# AST1060 register map
File version: 1.0
CPU: CM4 r0p1, little endian, MPU, FPU, 4 interrupt priority bits, 256 interrupts
Registers are 32-bit, read-write, reset 0x0 unless marked. A register's access mark holds for its fields unless they carry their own. Offsets are from the block's base; [hi:lo] are bit positions; {n}, {i} and the like mark numbered series; 'fields as' and 'values as' point back to an identical list.

## secure
Base 0x7E6F2000
0x00 SECURE000 — Protection Key Register
  [31:0] ProtKey — Protection Key
0x04 SECURE004 — OTP Command Trigger Register
  [31:0] OTPCmdTriggerReg
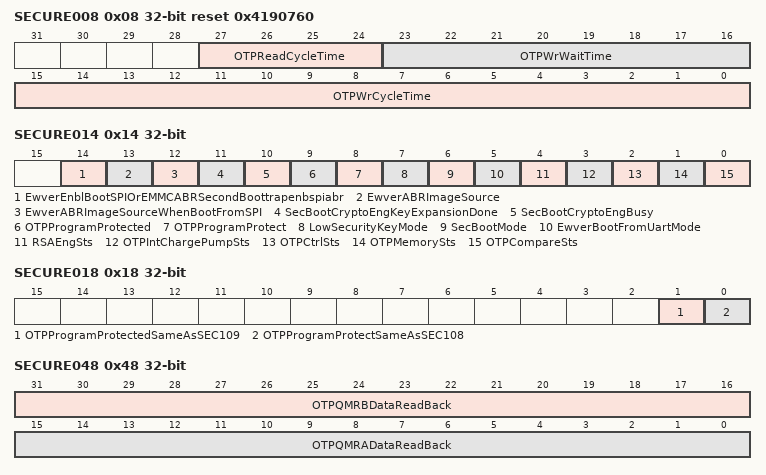
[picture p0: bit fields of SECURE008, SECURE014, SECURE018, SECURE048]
0x08 SECURE008 reset 0x4190760 — OTP Timing Register
  [27:24] OTPReadCycleTime
  [23:16] OTPWrWaitTime — OTP write wait time
  [15:0] OTPWrCycleTime — OTP write cycle time
0x10 SECURE010 — OTP Address Register
  [15:0] OTPAddrRegiste — OTP Address Registe
0x14 SECURE014 — Secure Engine Status Register
  [14] EwverEnblBootSPIOrEMMCABRSecondBoottrapenbspiabr ro — ewverEnable boot SPI or eMMC ABR (second boot)(trap_en_bspiabr
  [13] EwverABRImageSource ro
    0=First_ABR_Image; 1=Second_ABR_Image
  [12] EwverABRImageSourceWhenBootFromSPI ro
    0=First_ABR_Image_Source_When_Boot_From_SPI; 1=Second_ABR_Image_Source_When_Boot_From_SPI
  [11] SecBootCryptoEngKeyExpansionDone ro — Secure Boot Crypto Engine Key Expansion Done
    0=Crypto_Engine_Key_Expansion_Is_Busy; 1=Crypto_Engine_Key_Expansion_Is_Done
  [10] SecBootCryptoEngBusy ro — Secure Boot Crypto Engine Busy
    0=Crypto_Engine_Is_Idle; 1=Crypto_Engine_Is_Busy
  [9] OTPProgramProtected ro
    0=Last_OTP_Program_Command_Is_Completed; 1=Last_OTP_Program_Command_Is_Write_Protected
  [8] OTPProgramProtect ro
    0=SEC10_OTP_Address_Is_Not_Protected; 1=SEC10_OTP_Address_Is_Write_Protected
  [7] LowSecurityKeyMode ro
    0=Normal_Mode; 1=Low_Security_Mode_Is_Enabled
  [6] SecBootMode ro — Secure Boot Mode
    0=Normal_Mode; 1=Secure_Boot_Mode_Is_Enabled
  [5] EwverBootFromUartMode ro
    0=Boot_From_Uart_Mode; 1=Boot_From_SPI_Or_EMMC_Mode
  [4] RSAEngSts ro — RSA engine status
    0=RSA_Engine_Busy; 1=RSA_Engine_Ready
  [3] OTPIntChargePumpSts ro — OTP internal charge pump status
    0=OTP_Internal_Charge_Pump_Not_Ready; 1=OTP_Internal_Charge_Pump_Ready
  [2] OTPCtrlSts ro — OTP controller status
    0=OTP_Controller_Busy; 1=OTP_Controller_Idle
  [1] OTPMemorySts ro — OTP memory status
    0=OTP_Memory_Busy; 1=OTP_Memory_Idle
  [0] OTPCompareSts ro — OTP compare status
    0=Quad_DW_Read_Compare_Fail; 1=Quad_DW_Read_Compare_Pass
0x18 SECURE018 — OTP Programming Status Register
  [1] OTPProgramProtectedSameAsSEC109 ro
    values as SECURE014.OTPProgramProtected
  [0] OTPProgramProtectSameAsSEC108 ro
    values as SECURE014.OTPProgramProtect
0x20 SECURE020 — OTP Data Compare Register 1
  [31:0] OTPDataCompareReg1
0x24 SECURE024 — OTP Data Compare Register 2
  [31:0] OTPDataCompareReg2
0x28 SECURE028 — OTP Data Compare Register 3
  [31:0] OTPDataCompareReg3
0x2C SECURE02C — OTP Data Compare Register 4
  [31:0] OTPDataCompareReg4 ro
0x30 SECURE030 — OTPTRAP data read back 1
  [31:0] OTPTRAPDataReadBack1 ro
0x34 SECURE034 — OTPTRAP data read back 2
  [31:0] OTPTRAPDataReadBack2 ro
0x38 SECURE038 — OTP QRR data read back
  [31:0] OTPQRRDataReadBack ro
0x40 SECURE040 — OTP QSR data read back
  [31:0] OTPQSRDataReadBack ro
0x44 SECURE044 — OTP QMR data read back
  [31:0] OTPQMRDataReadBack ro
0x48 SECURE048 — OTP QMRA and QMRB data read back
  [31:16] OTPQMRBDataReadBack ro, [15:0] OTPQMRADataReadBack ro
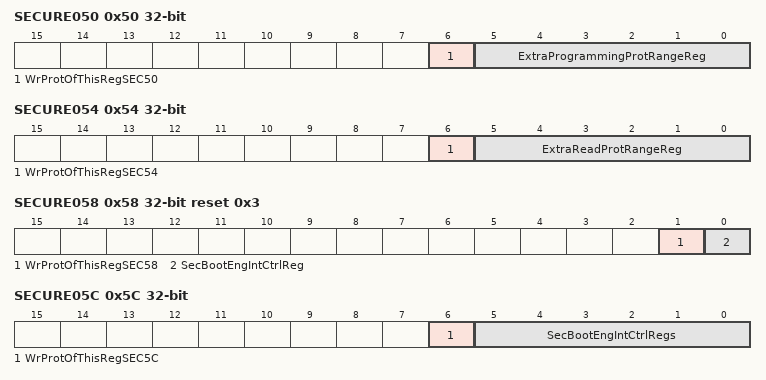
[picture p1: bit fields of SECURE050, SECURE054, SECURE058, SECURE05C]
0x50 SECURE050 (reset mask 0x3F) — Extra Programming Protection Range Register
  [6] WrProtOfThisRegSEC50 — Write Protection of this register SEC50
  [5:0] ExtraProgrammingProtRangeReg — Extra Programming Protection Range Register
0x54 SECURE054 — Extra Read Protection Range Register
  [6] WrProtOfThisRegSEC54 — Write Protection of this register SEC54
  [5:0] ExtraReadProtRangeReg — Extra Read Protection Range Register
0x58 SECURE058 reset 0x3 — Secure Boot Engine Internal Controller Register
  [1] WrProtOfThisRegSEC58 — Write Protection of this register SEC58
  [0] SecBootEngIntCtrlReg — Secure Boot Engine Internal Controller Register
0x5C SECURE05C (reset mask 0x1) — Secure Boot Engine Internal Controller Register
  [6] WrProtOfThisRegSEC5C — Write Protection of this register SEC5C
  [5:0] SecBootEngIntCtrlRegs — Secure Boot Engine Internal Controller Registers
0x60 SECURE060 — Secure Boot Hardware Revision Register 1
  [31:0] SecBootHwRevReg1
0x64 SECURE064 — Secure Boot Hardware Revision Register 2
  [31:0] SecBootHwRevReg2
0x68 SECURE068 — Secure Boot Software Revision Register 1
  [31:0] SecBootSwRevReg1
0x6C SECURE06C — Secure Boot Software Revision Register 2
  [31:0] SecBootSwRevReg2
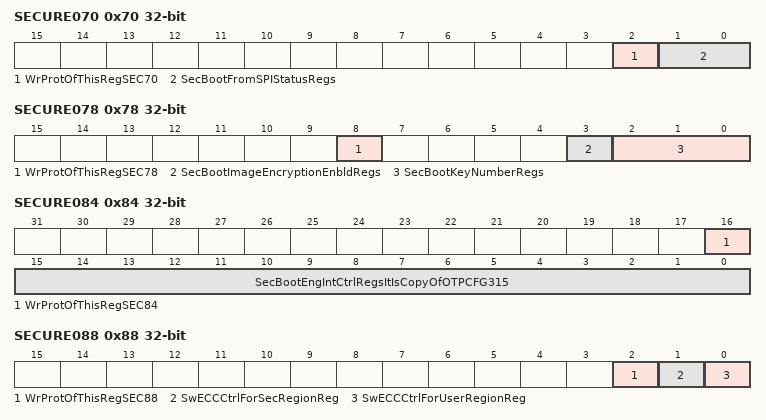
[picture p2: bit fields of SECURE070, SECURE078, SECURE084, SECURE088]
0x70 SECURE070 — Secure Boot from SPI Status Register
  [2] WrProtOfThisRegSEC70 — Write Protection of this register SEC70
  [1:0] SecBootFromSPIStatusRegs — Secure Boot from SPI Status Registers
    0=Reset_Initial_Value_And_During_Secure_Boot_Period_The_Value_Will_Keep_00_When_Secure_Boot_Is_Not_Enabled_Or_Boot_From_EMMC_Is_Enabled; 1=Secure_Boot_Check_Failed; 3=Secure_Boot_Check_Passed
0x78 SECURE078 — Secure Boot Key Number Register
  [8] WrProtOfThisRegSEC78 — Write Protection of this register SEC78
  [3] SecBootImageEncryptionEnbldRegs — Secure Boot Image Encryption Enabled Registers
  [2:0] SecBootKeyNumberRegs — Secure Boot Key Number Registers
0x80 SECURE080 — Secure Boot Engine Internal Controller Register
  [3:0] SecBootEngIntCtrlRegs — Secure Boot Engine Internal Controller Registers
0x84 SECURE084 — Secure Boot Engine Internal Controller Register
  [16] WrProtOfThisRegSEC84 — Write Protection of this register SEC84
  [15:0] SecBootEngIntCtrlRegsItIsCopyOfOTPCFG315 — 0]
0x88 SECURE088 — Software ECC Control Register
  [2] WrProtOfThisRegSEC88 — Write Protection of this register SEC88
  [1] SwECCCtrlForSecRegionReg — Software ECC Control for Secure Region Register
    0=Normal_Mode; 1=Disable_ECC_For_Secure_Region
  [0] SwECCCtrlForUserRegionReg — Software ECC Control for User Region Register
    0=Normal_Mode; 1=Disable_ECC_For_User_Region
0x8C SECURE08C — Secure Boot Engine Internal Controller Register
  [31:0] SecBootEngIntCtrlRegs — Secure Boot Engine Internal Controller Registers
0x90 SECURE090 — Secure Boot Counter Register
  [15:0] SecBootCounterReg ro
0x94 SECURE094 reset not defined — Secure Boot Counter 2 Register
0x98 SECURE098 — Secure Boot Engine Internal Controller Register
  [7:0] SecBootEngIntCtrlRegs — Secure Boot Engine Internal Controller Registers
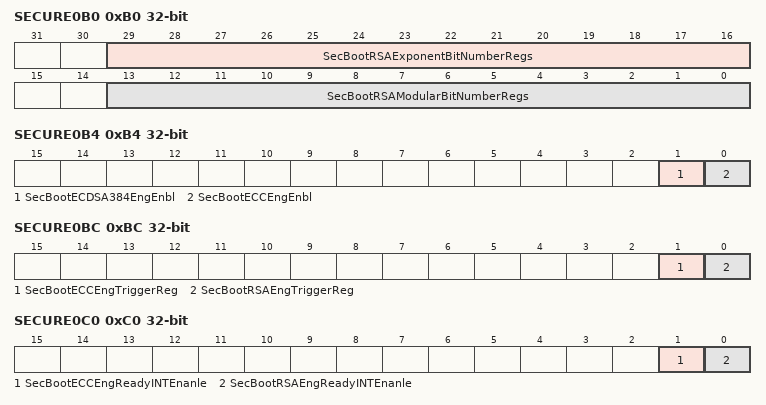
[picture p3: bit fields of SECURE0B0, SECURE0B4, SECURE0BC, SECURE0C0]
0xB0 SECURE0B0 — Secure Boot RSA Engine Controller Register
  [29:16] SecBootRSAExponentBitNumberRegs — Secure Boot RSA Exponent Bit Number Registers
  [13:0] SecBootRSAModularBitNumberRegs — Secure Boot RSA Modular Bit Number Registers
0xB4 SECURE0B4 — Secure Boot ECC Engine Controller Register
  [1] SecBootECDSA384EngEnbl — Secure Boot ECDSA384 Engine Enable
  [0] SecBootECCEngEnbl — Secure Boot ECC Engine Enable
0xBC SECURE0BC (reset mask 0x1) — Secure Boot Engine Trigger Register
  [1] SecBootECCEngTriggerReg — Secure Boot ECC Engine Trigger Register
  [0] SecBootRSAEngTriggerReg — Secure Boot RSA Engine Trigger Register
0xC0 SECURE0C0 — Secure Boot Engine Interrupt Controller Register
  [1] SecBootECCEngReadyINTEnanle — Secure Boot ECC Engine Ready Interrupt Enanle
  [0] SecBootRSAEngReadyINTEnanle — Secure Boot RSA Engine Ready Interrupt Enanle
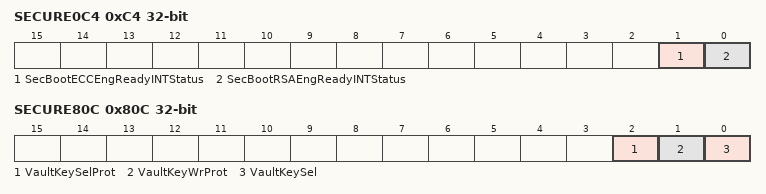
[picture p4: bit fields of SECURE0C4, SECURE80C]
0xC4 SECURE0C4 — Secure Boot Engine Interrupt Status Register
  [1] SecBootECCEngReadyINTStatus — Secure Boot ECC Engine Ready Interrupt Status
  [0] SecBootRSAEngReadyINTStatus — Secure Boot RSA Engine Ready Interrupt Status
0x800 SECURE800 reset not defined — Secure Boot DMA Enable Register
  [0] SecBootDMAEnblReg
    1=Trigger_Secure_Boot_DMA
0x808 SECURE808 — Secure Boot DMA Mode Register
  [5:0] SecBootDMAModeReg
0x80C SECURE80C — Secure Boot Vault Key Control Register
  [2] VaultKeySelProt — Vault Key Selection Protection
    0=Normal_Mode; 1=Disable_Write_Capability_Of_Register_SEC80C0
  [1] VaultKeyWrProt — Vault Key Write Protection
    0=Normal_Mode; 1=Disable_Write_Capability_Of_Registers_SEC900__SEC93C_
  [0] VaultKeySel — Vault Key Selection
    0=Select_First_Vault_Key_For_HACE; 1=Select_Second_Valut_Key_For_HACE
0x810 SECURE810 — Secure Boot Digest Status
  [0] SecBootDigestStatus
    0=Secure_Boot_Digest_Check_Fail_When_SEC81401; 1=Secure_Boot_Digest_Check_Pass_When_SEC81401
0x814 SECURE814 — Secure Boot Digest Check Status
  [0] SecBootDigestStatus — Secure Boot Digest Status
    0=Secure_Boot_Digest_Check_Idle; 1=Secure_Boot_Digest_Check_Busy
0x820 SECURE820 — Secure Crypto Engine Enable Register
  [0] SecCryptoEngEnblReg
    0=Secure_Crypto_Engine_Disable; 1=Secure_Crypto_Engine_Enable_HACE_Wont_Work_When_This_Mode
0x840 SECURE840 — Secure Boot DMA Source Address Register
  [31:2] SecBootDMASourceAddrReg
0x844 SECURE844 — Secure Boot DMA Destination Address Register
  [31:2] SecBootDMADestinationAddrReg
0x848 SECURE848 — Secure Boot DMA Size Register
  [16:0] SecBootDMASizeReg
0x854 SECURE854 — Secure Boot Hash Size Register
  [19:4] SecBootHashSizeReg
0x858 SECURE858 — Secure Boot Hash Mode Register
  [7:0] SecBootHashModeReg
0x85C SECURE85C — Secure Boot Hash Engine Fire Register
  [31:0] SecBootHashEngFireReg
0x860 SECURE860 — Secure Boot Crypto Mode Register
  [7:0] SecBootCryptoModeReg
0x864 SECURE864 — Secure Boot Crypto Data Size Register
  [19:4] SecBootCryptoDataSizeReg
0x868 SECURE868 — Secure Boot Crypto Data Total Size Register
  [12:0] SecBootCryptoDataTotalSizeReg
0x870 SECURE870 — Secure Boot Crypto Low Key Write Trigger Register
  [31:0] SecBootCryptoLowKeyWrTriggerReg
0x874 SECURE874 — Secure Boot Crypto High Key Write Trigger Register
  [31:0] SecBootCryptoHighKeyWrTriggerReg
0x878 SECURE878 — Secure Boot Crypto Vector Write Trigger Register
  [31:0] SecBootCryptoVectorWrTriggerReg
0x87C SECURE87C — Secure Boot Crypto Engine Fire Register
  [31:0] SecBootCryptoEngFireReg
0x880 SECURE880 — Secure Boot Crypto Data Buffer 0 Register
  [31:0] SecBootCryptoDataBuffer0Reg
0x884 SECURE884 — Secure Boot Crypto Data Buffer 1 Register
  [31:0] SecBootCryptoDataBuffer1Reg
0x888 SECURE888 — Secure Boot Crypto Data Buffer 2 Register
  [31:0] SecBootCryptoDataBuffer2Reg
0x88C SECURE88C — Secure Boot Crypto Data Buffer 3 Register
  [31:0] SecBootCryptoDataBuffer3Reg
0x890 SECURE890 — Secure Boot Crypto AES-GCM GHash Key Write Trigger Register
  [31:0] SecBootCryptoAESGCMGHashKeyWrTriggerReg
0x8A0 SECURE8A0 — Secure Boot Crypto Key Buffer 0 Register
  [31:0] SecBootCryptoKeyBuffer0Reg
0x8A4 SECURE8A4 — Secure Boot Crypto Key Buffer 1 Register
  [31:0] SecBootCryptoKeyBuffer1Reg
0x8A8 SECURE8A8 — Secure Boot Crypto Key Buffer 2 Register
  [31:0] SecBootCryptoKeyBuffer2Reg
0x8AC SECURE8AC — Secure Boot Crypto Key Buffer 3 Register
  [31:0] SecBootCryptoKeyBuffer3Reg
0x8B0 SECURE8B0 — Secure Boot Crypto Key Buffer 4 Register
  [31:0] SecBootCryptoKeyBuffer4Reg
0x8B4 SECURE8B4 — Secure Boot Crypto Key Buffer 5 Register
  [31:0] SecBootCryptoKeyBuffer5Reg
0x8B8 SECURE8B8 — Secure Boot Crypto Key Buffer 6 Register
  [31:0] SecBootCryptoKeyBuffer6Reg
0x8BC SECURE8BC — Secure Boot Crypto Key Buffer 7 Register
  [31:0] SecBootCryptoKeyBuffer7Reg
0x900 SECURE900 — Secure Boot First Vault Key 0 Register
  [31:0] SecBootFirstVaultKey0Reg
0x904 SECURE904 — Secure Boot First Vault Key 1 Register
  [31:0] SecBootFirstVaultKey1Reg
0x908 SECURE908 — Secure Boot First Vault Key 2 Register
  [31:0] SecBootFirstVaultKey2Reg
0x90C SECURE90C — Secure Boot First Vault Key 3 Register
  [31:0] SecBootFirstVaultKey3Reg
0x910 SECURE910 — Secure Boot First Vault Key 4 Register
  [31:0] SecBootFirstVaultKey4Reg
0x914 SECURE914 — Secure Boot First Vault Key 5 Register
  [31:0] SecBootFirstVaultKey5Reg
0x918 SECURE918 — Secure Boot First Vault Key 6 Register
  [31:0] SecBootFirstVaultKey6Reg
0x91C SECURE91C — Secure Boot First Vault Key 7 Register
  [31:0] SecBootFirstVaultKey7Reg
0x920 SECURE920 — Secure Boot Second Vault Key 0 Register
  [31:0] SecBootSecondVaultKey0Reg
0x924 SECURE924 — Secure Boot Second Vault Key 1 Register
  [31:0] SecBootSecondVaultKey1Reg
0x928 SECURE928 — Secure Boot Second Vault Key 2 Register
  [31:0] SecBootSecondVaultKey2Reg
0x92C SECURE92C — Secure Boot Second Vault Key 3 Register
  [31:0] SecBootSecondVaultKey3Reg
0x930 SECURE930 — Secure Boot Second Vault Key 4 Register
  [31:0] SecBootSecondVaultKey4Reg
0x934 SECURE934 — Secure Boot Second Vault Key 5 Register
  [31:0] SecBootSecondVaultKey5Reg
0x938 SECURE938 — Secure Boot Second Vault Key 6 Register
  [31:0] SecBootSecondVaultKey6Reg
0x93C SECURE93C — Secure Boot Second Vault Key 7 Register
  [31:0] SecBootSecondVaultKey7Reg
0x980 SECURE980 — Secure Boot Image Digest Read Back \#0 - \#16
  [31:0] SecBootImageDigestReadBack — Secure Boot Image Digest Read Back
0x984 SECURE984 — Secure Boot Image Digest Read Back \#0 - \#16
  fields as SECURE980
0x988 SECURE988 — Secure Boot Image Digest Read Back \#0 - \#16
  fields as SECURE980
0x98C SECURE98C — Secure Boot Image Digest Read Back \#0 - \#16
  fields as SECURE980
0x990 SECURE990 — Secure Boot Image Digest Read Back \#0 - \#16
  fields as SECURE980
0x994 SECURE994 — Secure Boot Image Digest Read Back \#0 - \#16
  fields as SECURE980
0x998 SECURE998 — Secure Boot Image Digest Read Back \#0 - \#16
  fields as SECURE980
0x99C SECURE99C — Secure Boot Image Digest Read Back \#0 - \#16
  fields as SECURE980
0x9A0 SECURE9A0 — Secure Boot Image Digest Read Back \#0 - \#16
  fields as SECURE980
0x9A4 SECURE9A4 — Secure Boot Image Digest Read Back \#0 - \#16
  fields as SECURE980
0x9A8 SECURE9A8 — Secure Boot Image Digest Read Back \#0 - \#16
  fields as SECURE980
0x9AC SECURE9AC — Secure Boot Image Digest Read Back \#0 - \#16
  fields as SECURE980
0x9B0 SECURE9B0 — Secure Boot Image Digest Read Back \#0 - \#16
  fields as SECURE980
0x9B4 SECURE9B4 — Secure Boot Image Digest Read Back \#0 - \#16
  fields as SECURE980
0x9B8 SECURE9B8 — Secure Boot Image Digest Read Back \#0 - \#16
  fields as SECURE980
0x9BC SECURE9BC — Secure Boot Image Digest Read Back \#0 - \#16
  fields as SECURE980
0xA00 SECUREA00 — Secure Boot ECC Default Public Key Read Back \#0 - \#16
  [31:0] SecBootECCDefaultPublicKeyReadBack — Secure Boot ECC Default Public Key Read Back
0xA04 SECUREA04 — Secure Boot ECC Default Public Key Read Back \#0 - \#16
  fields as SECUREA00
0xA08 SECUREA08 — Secure Boot ECC Default Public Key Read Back \#0 - \#16
  fields as SECUREA00
{0xA0C+0x10*i} SECUREA{i}C (i=0..9) — Secure Boot ECC Default Public Key Read Back \#0 - \#16
  fields as SECUREA00
0xA10 SECUREA10 — Secure Boot ECC Default Public Key Read Back \#0 - \#16
  fields as SECUREA00
0xA14 SECUREA14 — Secure Boot ECC Default Public Key Read Back \#0 - \#16
  fields as SECUREA00
0xA18 SECUREA18 — Secure Boot ECC Default Public Key Read Back \#0 - \#16
  fields as SECUREA00
0xA20 SECUREA20 — Secure Boot ECC Default Public Key Read Back \#0 - \#16
  fields as SECUREA00
0xA24 SECUREA24 — Secure Boot ECC Default Public Key Read Back \#0 - \#16
  fields as SECUREA00
0xA28 SECUREA28 — Secure Boot ECC Default Public Key Read Back \#0 - \#16
  fields as SECUREA00
0xA30 SECUREA30 — Secure Boot ECC Default Public Key Read Back \#0 - \#16
  fields as SECUREA00
0xA34 SECUREA34 — Secure Boot ECC Default Public Key Read Back \#0 - \#16
  fields as SECUREA00
0xA38 SECUREA38 — Secure Boot ECC Default Public Key Read Back \#0 - \#16
  fields as SECUREA00
0xA40 SECUREA40 — Secure Boot ECC Default Public Key Read Back \#0 - \#16
  fields as SECUREA00
0xA44 SECUREA44 — Secure Boot ECC Default Public Key Read Back \#0 - \#16
  fields as SECUREA00
0xA48 SECUREA48 — Secure Boot ECC Default Public Key Read Back \#0 - \#16
  fields as SECUREA00
0xA50 SECUREA50 — Secure Boot ECC Default Public Key Read Back \#0 - \#16
  fields as SECUREA00
0xA54 SECUREA54 — Secure Boot ECC Default Public Key Read Back \#0 - \#16
  fields as SECUREA00
0xA58 SECUREA58 — Secure Boot ECC Default Public Key Read Back \#0 - \#16
  fields as SECUREA00
0xA60 SECUREA60 — Secure Boot ECC Default Public Key Read Back \#0 - \#16
  fields as SECUREA00
0xA64 SECUREA64 — Secure Boot ECC Default Public Key Read Back \#0 - \#16
  fields as SECUREA00
0xA68 SECUREA68 — Secure Boot ECC Default Public Key Read Back \#0 - \#16
  fields as SECUREA00
0xA70 SECUREA70 — Secure Boot ECC Default Public Key Read Back \#0 - \#16
  fields as SECUREA00
0xA74 SECUREA74 — Secure Boot ECC Default Public Key Read Back \#0 - \#16
  fields as SECUREA00
0xA78 SECUREA78 — Secure Boot ECC Default Public Key Read Back \#0 - \#16
  fields as SECUREA00
0xA80 SECUREA80 — Secure Boot ECC Default Public Key Read Back \#0 - \#16
  fields as SECUREA00
0xA84 SECUREA84 — Secure Boot ECC Default Public Key Read Back \#0 - \#16
  fields as SECUREA00
0xA88 SECUREA88 — Secure Boot ECC Default Public Key Read Back \#0 - \#16
  fields as SECUREA00
0xA90 SECUREA90 — Secure Boot ECC Default Public Key Read Back \#0 - \#16
  fields as SECUREA00
0xA94 SECUREA94 — Secure Boot ECC Default Public Key Read Back \#0 - \#16
  fields as SECUREA00
0xA98 SECUREA98 — Secure Boot ECC Default Public Key Read Back \#0 - \#16
  fields as SECUREA00
0xAA0 SECUREAA0 — Secure Boot ECC Default Public Key Read Back \#0 - \#16
  fields as SECUREA00
0xAA4 SECUREAA4 — Secure Boot ECC Default Public Key Read Back \#0 - \#16
  fields as SECUREA00
0xAA8 SECUREAA8 — Secure Boot ECC Default Public Key Read Back \#0 - \#16
  fields as SECUREA00
0xAAC SECUREAAC — Secure Boot ECC Default Public Key Read Back \#0 - \#16
  fields as SECUREA00
0xAB0 SECUREAB0 — Secure Boot ECC Default Public Key Read Back \#0 - \#16
  fields as SECUREA00
0xAB4 SECUREAB4 — Secure Boot ECC Default Public Key Read Back \#0 - \#16
  fields as SECUREA00
0xAB8 SECUREAB8 — Secure Boot ECC Default Public Key Read Back \#0 - \#16
  fields as SECUREA00
0xABC SECUREABC — Secure Boot ECC Default Public Key Read Back \#0 - \#16
  fields as SECUREA00
0xAC0 SECUREAC0 — Secure Boot ECC Default Public Key Read Back \#0 - \#16
  fields as SECUREA00
0xAC4 SECUREAC4 — Secure Boot ECC Default Public Key Read Back \#0 - \#16
  fields as SECUREA00
0xAC8 SECUREAC8 — Secure Boot ECC Default Public Key Read Back \#0 - \#16
  fields as SECUREA00
0xACC SECUREACC — Secure Boot ECC Default Public Key Read Back \#0 - \#16
  fields as SECUREA00
0xAD0 SECUREAD0 — Secure Boot ECC Default Public Key Read Back \#0 - \#16
  fields as SECUREA00
0xAD4 SECUREAD4 — Secure Boot ECC Default Public Key Read Back \#0 - \#16
  fields as SECUREA00
0xAD8 SECUREAD8 — Secure Boot ECC Default Public Key Read Back \#0 - \#16
  fields as SECUREA00
0xADC SECUREADC — Secure Boot ECC Default Public Key Read Back \#0 - \#16
  fields as SECUREA00
0xAE0 SECUREAE0 — Secure Boot ECC Default Public Key Read Back \#0 - \#16
  fields as SECUREA00
0xAE4 SECUREAE4 — Secure Boot ECC Default Public Key Read Back \#0 - \#16
  fields as SECUREA00
0xAE8 SECUREAE8 — Secure Boot ECC Default Public Key Read Back \#0 - \#16
  fields as SECUREA00
0xAEC SECUREAEC — Secure Boot ECC Default Public Key Read Back \#0 - \#16
  fields as SECUREA00
